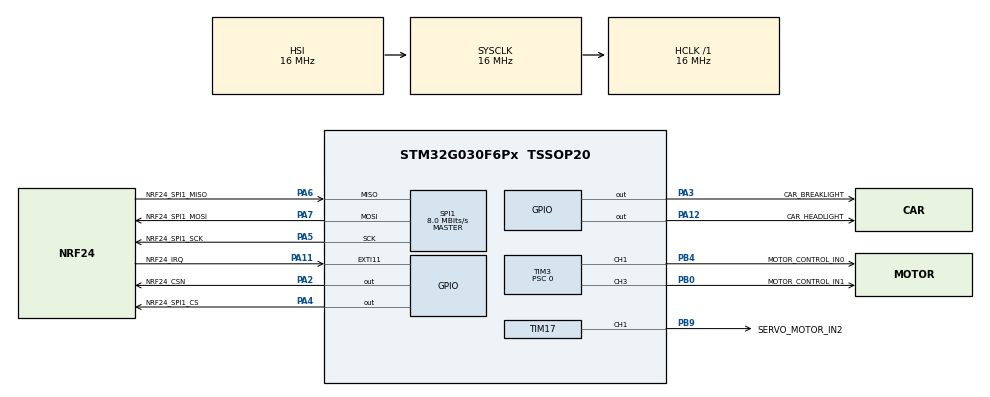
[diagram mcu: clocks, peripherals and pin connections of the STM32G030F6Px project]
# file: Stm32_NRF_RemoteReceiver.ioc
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Mcu.Family=STM32G0
Mcu.Name=STM32G030F6Px
Mcu.Package=TSSOP20
NVIC.EXTI4_15_IRQn=true\:0\:0\:false\:false\:true\:true\:true\:true
NVIC.TIM17_IRQn=true\:0\:0\:false\:false\:true\:true\:true\:true
NVIC.TIM3_IRQn=true\:0\:0\:false\:false\:true\:true\:true\:true
PA11\ [PA9].GPIO_Label=NRF24_IRQ
PA11\ [PA9].GPIO_ModeDefaultEXTI=GPIO_MODE_IT_FALLING
PA11\ [PA9].GPIO_PuPd=GPIO_NOPULL
PA11\ [PA9].Signal=GPXTI11
PA12\ [PA10].GPIO_Label=CAR_HEADLIGHT
PA12\ [PA10].Signal=GPIO_Output
PA13.Mode=Serial_Wire
PA13.Signal=SYS_SWDIO
PA14-BOOT0.Mode=Serial_Wire
PA14-BOOT0.Signal=SYS_SWCLK
PA14-BOOT0__PA15.StandardMode=true
PA2.GPIO_Label=NRF24_CSN
PA2.Signal=GPIO_Output
PA3.GPIO_Label=CAR_BREAKLIGHT
PA3.Signal=GPIO_Output
PA4.GPIO_Label=NRF24_SPI1_CS
PA4.Signal=GPIO_Output
PA5.GPIO_Label=NRF24_SPI1_SCK
PA5.Mode=Full_Duplex_Master
PA5.Signal=SPI1_SCK
PA6.GPIO_Label=NRF24_SPI1_MISO
PA6.Mode=Full_Duplex_Master
PA6.Signal=SPI1_MISO
PA7.GPIO_Label=NRF24_SPI1_MOSI
PA7.Mode=Full_Duplex_Master
PA7.Signal=SPI1_MOSI
PB0.GPIO_Label=MOTOR_CONTROL_IN1
PB0.Signal=S_TIM3_CH3
PB0__PB1__PB2__PA8.StandardMode=true
PB3__PB4__PB5__PB6.StandardMode=true
PB4.GPIO_Label=MOTOR_CONTROL_IN0
PB4.Signal=S_TIM3_CH1
PB7__PB8.StandardMode=true
PB9.GPIO_Label=SERVO_MOTOR_IN2
PB9.Signal=S_TIM17_CH1
PC14-OSC32_IN\ (PC14)__PB9.StandardMode=true
ProjectManager.HeapSize=0x200
ProjectManager.StackSize=0x400
ProjectManager.TargetToolchain=STM32CubeIDE
RCC.ADCFreq_Value=16000000
RCC.AHBFreq_Value=16000000
RCC.CortexFreq_Value=16000000
RCC.EXTERNAL_CLOCK_VALUE=12288000
RCC.HCLKFreq_Value=16000000
RCC.HSE_VALUE=8000000
RCC.HSI_VALUE=16000000
RCC.LSE_VALUE=32768
RCC.SYSCLKFreq_VALUE=16000000
RCC.VCOOutputFreq_Value=128000000
SH.S_TIM17_CH1.0=TIM17_CH1,PWM Generation1 CH1
SH.S_TIM3_CH1.0=TIM3_CH1,PWM Generation1 CH1
SH.S_TIM3_CH3.0=TIM3_CH3,PWM Generation3 CH3
SPI1.CalculateBaudRate=8.0 MBits/s
SPI1.Direction=SPI_DIRECTION_2LINES
SPI1.Mode=SPI_MODE_MASTER
SPI1.VirtualType=VM_MASTER
TIM17.Channel=TIM_CHANNEL_1
TIM3.AutoReloadPreload=TIM_AUTORELOAD_PRELOAD_ENABLE
TIM3.Channel-PWM\ Generation1\ CH1=TIM_CHANNEL_1
TIM3.Channel-PWM\ Generation3\ CH3=TIM_CHANNEL_3
TIM3.Prescaler=0
VP_TIM17_VS_ClockSourceINT.Mode=Enable_Timer
board=custom

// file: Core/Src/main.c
/* USER CODE BEGIN Header */
/**
  ******************************************************************************
  * @file           : main.c
  * @brief          : Main program body
  ******************************************************************************
  * @attention
  *
  * Copyright (c) 2024 STMicroelectronics.
  * All rights reserved.
  *
  * This software is licensed under terms that can be found in the LICENSE file
  * in the root directory of this software component.
  * If no LICENSE file comes with this software, it is provided AS-IS.
  *
  ******************************************************************************
  */
/* USER CODE END Header */
#include "main.h"

/* USER CODE BEGIN Includes */
#include "app.h"
#include "nrf24.h"
/* USER CODE END Includes */

SPI_HandleTypeDef hspi1;

TIM_HandleTypeDef htim3;
TIM_HandleTypeDef htim17;

/* USER CODE BEGIN PV */
TIM_OC_InitTypeDef ConfigOcM0 = {0};
TIM_OC_InitTypeDef ConfigOcM1 = {0};
uint8_t ControlData = 0;
uint8_t duty = 70;
/* USER CODE END PV */

void SystemClock_Config(void);
static void MX_GPIO_Init(void);
static void MX_SPI1_Init(void);
static void MX_TIM3_Init(void);
static void MX_TIM17_Init(void);

int main(void)
{

  /* MCU Configuration--------------------------------------------------------*/

  /* Reset of all peripherals, Initializes the Flash interface and the Systick. */
  HAL_Init();

  /* Configure the system clock */
  SystemClock_Config();

  /* Initialize all configured peripherals */
  MX_GPIO_Init();
  MX_SPI1_Init();
  MX_TIM3_Init();
  MX_TIM17_Init();

  /* USER CODE BEGIN 2 */
  App_Init();
  App_Main();
  /* USER CODE END 2 */

  /* Infinite loop */
    while (1)
    {

    }
}

void SystemClock_Config(void)
{
  RCC_OscInitTypeDef RCC_OscInitStruct = {0};
  RCC_ClkInitTypeDef RCC_ClkInitStruct = {0};

  /** Configure the main internal regulator output voltage
  */
  HAL_PWREx_ControlVoltageScaling(PWR_REGULATOR_VOLTAGE_SCALE1);

  /** Initializes the RCC Oscillators according to the specified parameters
  * in the RCC_OscInitTypeDef structure.
  */
  RCC_OscInitStruct.OscillatorType = RCC_OSCILLATORTYPE_HSI;
  RCC_OscInitStruct.HSIState = RCC_HSI_ON;
  RCC_OscInitStruct.HSIDiv = RCC_HSI_DIV1;
  RCC_OscInitStruct.HSICalibrationValue = RCC_HSICALIBRATION_DEFAULT;
  RCC_OscInitStruct.PLL.PLLState = RCC_PLL_NONE;
  if (HAL_RCC_OscConfig(&RCC_OscInitStruct) != HAL_OK)
  {
    Error_Handler();
  }

  /** Initializes the CPU, AHB and APB buses clocks
  */
  RCC_ClkInitStruct.ClockType = RCC_CLOCKTYPE_HCLK|RCC_CLOCKTYPE_SYSCLK
                              |RCC_CLOCKTYPE_PCLK1;
  RCC_ClkInitStruct.SYSCLKSource = RCC_SYSCLKSOURCE_HSI;
  RCC_ClkInitStruct.AHBCLKDivider = RCC_SYSCLK_DIV1;
  RCC_ClkInitStruct.APB1CLKDivider = RCC_HCLK_DIV1;

  if (HAL_RCC_ClockConfig(&RCC_ClkInitStruct, FLASH_LATENCY_0) != HAL_OK)
  {
    Error_Handler();
  }
}

static void MX_SPI1_Init(void)
{

  /* SPI1 parameter configuration*/
  hspi1.Instance = SPI1;
  hspi1.Init.Mode = SPI_MODE_MASTER;
  hspi1.Init.Direction = SPI_DIRECTION_2LINES;
  hspi1.Init.DataSize = SPI_DATASIZE_8BIT;
  hspi1.Init.CLKPolarity = SPI_POLARITY_LOW;
  hspi1.Init.CLKPhase = SPI_PHASE_1EDGE;
  hspi1.Init.NSS = SPI_NSS_SOFT;
  hspi1.Init.BaudRatePrescaler = SPI_BAUDRATEPRESCALER_2;
  hspi1.Init.FirstBit = SPI_FIRSTBIT_MSB;
  hspi1.Init.TIMode = SPI_TIMODE_DISABLE;
  hspi1.Init.CRCCalculation = SPI_CRCCALCULATION_DISABLE;
  hspi1.Init.CRCPolynomial = 7;
  hspi1.Init.CRCLength = SPI_CRC_LENGTH_DATASIZE;
  hspi1.Init.NSSPMode = SPI_NSS_PULSE_ENABLE;
  if (HAL_SPI_Init(&hspi1) != HAL_OK)
  {
    Error_Handler();
  }

}

static void MX_TIM3_Init(void)
{

  TIM_MasterConfigTypeDef sMasterConfig = {0};
  TIM_OC_InitTypeDef sConfigOC = {0};

  htim3.Instance = TIM3;
  htim3.Init.Prescaler = 0;
  htim3.Init.CounterMode = TIM_COUNTERMODE_UP;
  htim3.Init.Period = 65535;
  htim3.Init.ClockDivision = TIM_CLOCKDIVISION_DIV1;
  htim3.Init.AutoReloadPreload = TIM_AUTORELOAD_PRELOAD_ENABLE;
  if (HAL_TIM_PWM_Init(&htim3) != HAL_OK)
  {
    Error_Handler();
  }
  sMasterConfig.MasterOutputTrigger = TIM_TRGO_RESET;
  sMasterConfig.MasterSlaveMode = TIM_MASTERSLAVEMODE_DISABLE;
  if (HAL_TIMEx_MasterConfigSynchronization(&htim3, &sMasterConfig) != HAL_OK)
  {
    Error_Handler();
  }
  sConfigOC.OCMode = TIM_OCMODE_PWM1;
  sConfigOC.Pulse = 0;
  sConfigOC.OCPolarity = TIM_OCPOLARITY_HIGH;
  sConfigOC.OCFastMode = TIM_OCFAST_DISABLE;
  if (HAL_TIM_PWM_ConfigChannel(&htim3, &sConfigOC, TIM_CHANNEL_1) != HAL_OK)
  {
    Error_Handler();
  }
  if (HAL_TIM_PWM_ConfigChannel(&htim3, &sConfigOC, TIM_CHANNEL_3) != HAL_OK)
  {
    Error_Handler();
  }
  /* USER CODE BEGIN TIM3_Init 2 */
  ConfigOcM0 = sConfigOC;
  /* USER CODE END TIM3_Init 2 */
  HAL_TIM_MspPostInit(&htim3);

}

static void MX_TIM17_Init(void)
{

  TIM_OC_InitTypeDef sConfigOC = {0};
  TIM_BreakDeadTimeConfigTypeDef sBreakDeadTimeConfig = {0};

  htim17.Instance = TIM17;
  htim17.Init.Prescaler = 0;
  htim17.Init.CounterMode = TIM_COUNTERMODE_UP;
  htim17.Init.Period = 65535;
  htim17.Init.ClockDivision = TIM_CLOCKDIVISION_DIV1;
  htim17.Init.RepetitionCounter = 0;
  htim17.Init.AutoReloadPreload = TIM_AUTORELOAD_PRELOAD_DISABLE;
  if (HAL_TIM_Base_Init(&htim17) != HAL_OK)
  {
    Error_Handler();
  }
  if (HAL_TIM_PWM_Init(&htim17) != HAL_OK)
  {
    Error_Handler();
  }
  sConfigOC.OCMode = TIM_OCMODE_PWM1;
  sConfigOC.Pulse = 0;
  sConfigOC.OCPolarity = TIM_OCPOLARITY_HIGH;
  sConfigOC.OCNPolarity = TIM_OCNPOLARITY_HIGH;
  sConfigOC.OCFastMode = TIM_OCFAST_DISABLE;
  sConfigOC.OCIdleState = TIM_OCIDLESTATE_RESET;
  sConfigOC.OCNIdleState = TIM_OCNIDLESTATE_RESET;
  if (HAL_TIM_PWM_ConfigChannel(&htim17, &sConfigOC, TIM_CHANNEL_1) != HAL_OK)
  {
    Error_Handler();
  }
  sBreakDeadTimeConfig.OffStateRunMode = TIM_OSSR_DISABLE;
  sBreakDeadTimeConfig.OffStateIDLEMode = TIM_OSSI_DISABLE;
  sBreakDeadTimeConfig.LockLevel = TIM_LOCKLEVEL_OFF;
  sBreakDeadTimeConfig.DeadTime = 0;
  sBreakDeadTimeConfig.BreakState = TIM_BREAK_DISABLE;
  sBreakDeadTimeConfig.BreakPolarity = TIM_BREAKPOLARITY_HIGH;
  sBreakDeadTimeConfig.BreakFilter = 0;
  sBreakDeadTimeConfig.AutomaticOutput = TIM_AUTOMATICOUTPUT_DISABLE;
  if (HAL_TIMEx_ConfigBreakDeadTime(&htim17, &sBreakDeadTimeConfig) != HAL_OK)
  {
    Error_Handler();
  }
  /* USER CODE BEGIN TIM17_Init 2 */
  ConfigOcM1 = sConfigOC;
  /* USER CODE END TIM17_Init 2 */
  HAL_TIM_MspPostInit(&htim17);

}

static void MX_GPIO_Init(void)
{
  GPIO_InitTypeDef GPIO_InitStruct = {0};

  /* GPIO Ports Clock Enable */
  __HAL_RCC_GPIOB_CLK_ENABLE();
  __HAL_RCC_GPIOA_CLK_ENABLE();

  /*Configure GPIO pin Output Level */
  HAL_GPIO_WritePin(GPIOA, NRF24_CSN_Pin|CAR_BREAKLIGHT_Pin|NRF24_SPI1_CS_Pin|CAR_HEADLIGHT_Pin, GPIO_PIN_RESET);

  /*Configure GPIO pins : NRF24_CSN_Pin CAR_BREAKLIGHT_Pin NRF24_SPI1_CS_Pin CAR_HEADLIGHT_Pin */
  GPIO_InitStruct.Pin = NRF24_CSN_Pin|CAR_BREAKLIGHT_Pin|NRF24_SPI1_CS_Pin|CAR_HEADLIGHT_Pin;
  GPIO_InitStruct.Mode = GPIO_MODE_OUTPUT_PP;
  GPIO_InitStruct.Pull = GPIO_NOPULL;
  GPIO_InitStruct.Speed = GPIO_SPEED_FREQ_LOW;
  HAL_GPIO_Init(GPIOA, &GPIO_InitStruct);

  /*Configure GPIO pin : NRF24_IRQ_Pin */
  GPIO_InitStruct.Pin = NRF24_IRQ_Pin;
  GPIO_InitStruct.Mode = GPIO_MODE_IT_FALLING;
  GPIO_InitStruct.Pull = GPIO_NOPULL;
  HAL_GPIO_Init(NRF24_IRQ_GPIO_Port, &GPIO_InitStruct);

  /* EXTI interrupt init*/
  HAL_NVIC_SetPriority(EXTI4_15_IRQn, 0, 0);
  HAL_NVIC_EnableIRQ(EXTI4_15_IRQn);

}

void Error_Handler(void)
{
    __disable_irq();
    while (1)
    {
    }
}
